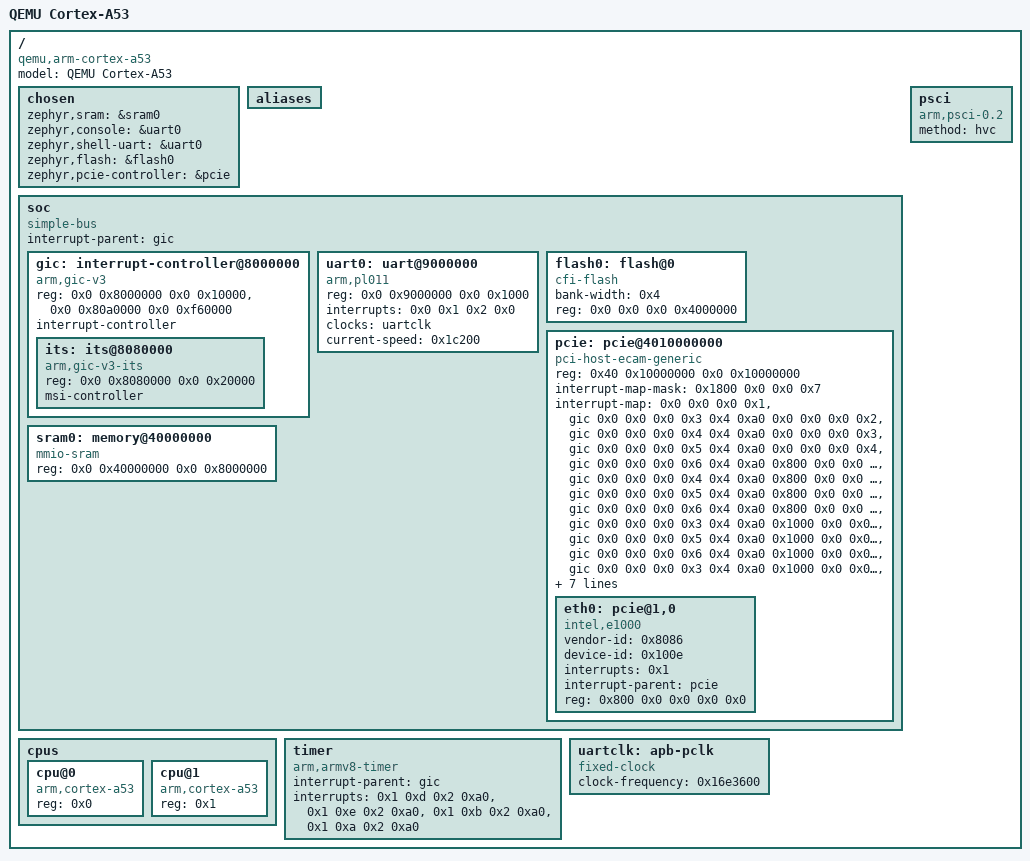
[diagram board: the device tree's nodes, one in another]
/dts-v1/;

/ {
	#address-cells = < 0x2 >;
	#size-cells = < 0x2 >;
	model = "QEMU Cortex-A53";
	compatible = "qemu,arm-cortex-a53";
	chosen {
		zephyr,sram = &sram0;
		zephyr,console = &uart0;
		zephyr,shell-uart = &uart0;
		zephyr,flash = &flash0;
		zephyr,pcie-controller = &pcie;
	};
	aliases {
	};
	soc {
		#address-cells = < 0x2 >;
		#size-cells = < 0x2 >;
		compatible = "simple-bus";
		ranges;
		interrupt-parent = < &gic >;
		gic: interrupt-controller@8000000 {
			compatible = "arm,gic-v3", "arm,gic";
			reg = < 0x0 0x8000000 0x0 0x10000 >, < 0x0 0x80a0000 0x0 0xf60000 >;
			interrupt-controller;
			#interrupt-cells = < 0x4 >;
			status = "okay";
			#size-cells = < 0x2 >;
			#address-cells = < 0x2 >;
			phandle = < 0x1 >;
			its: its@8080000 {
				compatible = "arm,gic-v3-its";
				reg = < 0x0 0x8080000 0x0 0x20000 >;
				msi-controller;
				phandle = < 0x3 >;
			};
		};
		uart0: uart@9000000 {
			compatible = "arm,pl011";
			reg = < 0x0 0x9000000 0x0 0x1000 >;
			status = "okay";
			interrupts = < 0x0 0x1 0x2 0x0 >;
			interrupt-names = "irq_0";
			clocks = < &uartclk >;
			current-speed = < 0x1c200 >;
		};
		flash0: flash@0 {
			compatible = "cfi-flash";
			bank-width = < 0x4 >;
			reg = < 0x0 0x0 0x0 0x4000000 >;
		};
		pcie: pcie@4010000000 {
			compatible = "pci-host-ecam-generic";
			device_type = "pci";
			reg = < 0x40 0x10000000 0x0 0x10000000 >;
			#size-cells = < 0x2 >;
			#address-cells = < 0x3 >;
			ranges = < 0x1000000 0x0 0x0 0x0 0x3eff0000 0x0 0x10000 0x2000000 0x0 0x10000000 0x0 0x10000000 0x0 0x2eff0000 0x3000000 0x80 0x0 0x80 0x0 0x80 0x0 >;
			#interrupt-cells = < 0x1 >;
			interrupt-map-mask = < 0x1800 0x0 0x0 0x7 >;
			interrupt-map = < 0x0 0x0 0x0 0x1 &gic 0x0 0x0 0x0 0x3 0x4 0xa0 0x0 0x0 0x0 0x2 &gic 0x0 0x0 0x0 0x4 0x4 0xa0 0x0 0x0 0x0 0x3 &gic 0x0 0x0 0x0 0x5 0x4 0xa0 0x0 0x0 0x0 0x4 &gic 0x0 0x0 0x0 0x6 0x4 0xa0 0x800 0x0 0x0 0x1 &gic 0x0 0x0 0x0 0x4 0x4 0xa0 0x800 0x0 0x0 0x2 &gic 0x0 0x0 0x0 0x5 0x4 0xa0 0x800 0x0 0x0 0x3 &gic 0x0 0x0 0x0 0x6 0x4 0xa0 0x800 0x0 0x0 0x4 &gic 0x0 0x0 0x0 0x3 0x4 0xa0 0x1000 0x0 0x0 0x1 &gic 0x0 0x0 0x0 0x5 0x4 0xa0 0x1000 0x0 0x0 0x2 &gic 0x0 0x0 0x0 0x6 0x4 0xa0 0x1000 0x0 0x0 0x3 &gic 0x0 0x0 0x0 0x3 0x4 0xa0 0x1000 0x0 0x0 0x4 &gic 0x0 0x0 0x0 0x4 0x4 0xa0 0x1800 0x0 0x0 0x1 &gic 0x0 0x0 0x0 0x6 0x4 0xa0 0x1800 0x0 0x0 0x2 &gic 0x0 0x0 0x0 0x3 0x4 0xa0 0x1800 0x0 0x0 0x3 &gic 0x0 0x0 0x0 0x4 0x4 0xa0 0x1800 0x0 0x0 0x4 &gic 0x0 0x0 0x0 0x5 0x4 0xa0 >;
			msi-parent = < &its >;
			bus-range = < 0x0 0xff >;
			phandle = < 0x4 >;
			eth0: pcie@1,0 {
				compatible = "intel,e1000";
				vendor-id = < 0x8086 >;
				device-id = < 0x100e >;
				interrupts = < 0x1 >;
				interrupt-parent = < &pcie >;
				reg = < 0x800 0x0 0x0 0x0 0x0 >;
				status = "okay";
			};
		};
		sram0: memory@40000000 {
			compatible = "mmio-sram";
			reg = < 0x0 0x40000000 0x0 0x8000000 >;
		};
	};
	cpus {
		#address-cells = < 0x1 >;
		#size-cells = < 0x0 >;
		cpu@0 {
			device_type = "cpu";
			compatible = "arm,cortex-a53";
			reg = < 0x0 >;
		};
		cpu@1 {
			device_type = "cpu";
			compatible = "arm,cortex-a53";
			reg = < 0x1 >;
		};
	};
	timer {
		compatible = "arm,armv8-timer";
		interrupt-parent = < &gic >;
		interrupts = < 0x1 0xd 0x2 0xa0 >, < 0x1 0xe 0x2 0xa0 >, < 0x1 0xb 0x2 0xa0 >, < 0x1 0xa 0x2 0xa0 >;
	};
	uartclk: apb-pclk {
		compatible = "fixed-clock";
		clock-frequency = < 0x16e3600 >;
		#clock-cells = < 0x0 >;
		phandle = < 0x2 >;
	};
	psci {
		compatible = "arm,psci-0.2";
		method = "hvc";
	};
};
